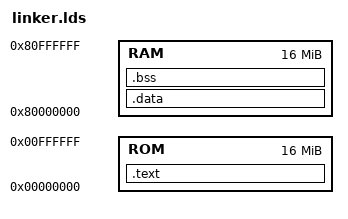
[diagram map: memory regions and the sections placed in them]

ENTRY(_start)

MEMORY
{
        ROM : ORIGIN = 0x00000000, LENGTH = 16M
        RAM : ORIGIN = 0x80000000, LENGTH = 16M
}

SECTIONS
{
        /**********************************************************************
         *                                                                    *
         **********************************************************************/
        .text :
        {
                _stext = .;
                *(.startup)
                *(.text)
                *(.text.*)
                *(.rodata)
                *(.rodata.*)
                *(.srodata)
                *(.srodata.*)
                . = ALIGN(0x10);
                _etext = .;
        } > ROM
        /**********************************************************************
         *                                                                    *
         **********************************************************************/
        .data : AT(_etext)
        {
                _sdata = .;
                *(.data)
                *(.data.*)
                *(.sdata)
                *(.sdata.*)
                *(.sdata2)
                *(.sdata2.*)
                . = ALIGN(0x10);
                _edata = .;
        } > RAM
        /**********************************************************************
         *                                                                    *
         **********************************************************************/
        .bss ADDR(.data) + SIZEOF(.data) (NOLOAD) :
        {
                _sbss = .;
                *(.bss)
                *(.bss.*)
                *(COMMON)
                _ebss = .;
        } > RAM
        /**********************************************************************
         *                                                                    *
         **********************************************************************/
        .debug_info     : { *(.debug_info) }
        .debug_abbrev   : { *(.debug_abbrev) }
        .debug_aranges  : { *(.debug_aranges) }
        .debug_frame    : { *(.debug_frame) }
        .debug_line     : { *(.debug_line) }
        .debug_line_str : { *(.debug_line_str) }
        .debug_loclists : { *(.debug_loclists) }
        .debug_macro    : { *(.debug_macro) }
        .debug_names    : { *(.debug_names) }
        .debug_rnglists : { *(.debug_rnglists) }
        .debug_str      : { *(.debug_str) }
        /**********************************************************************
         *                                                                    *
         **********************************************************************/
        /DISCARD/ :
        {
                *(.comment)
                *(.eh_frame)
        }
}

